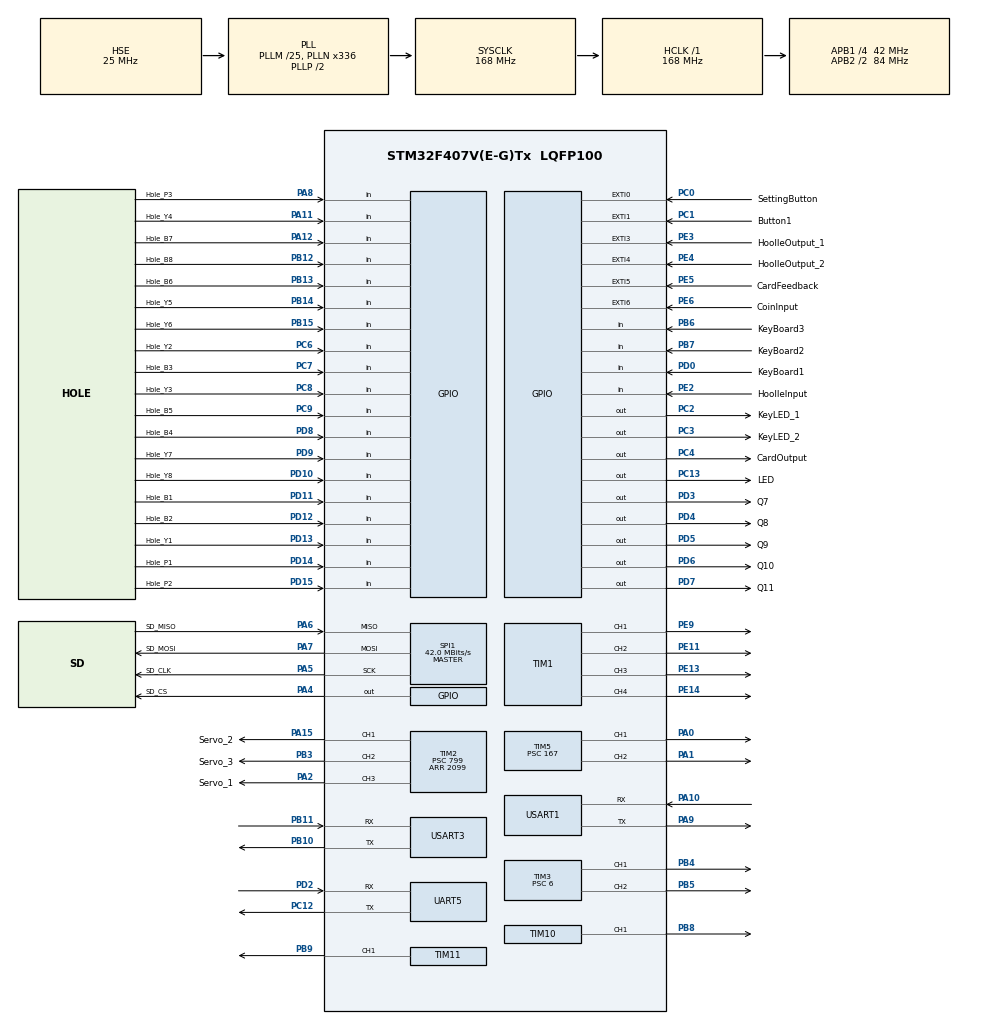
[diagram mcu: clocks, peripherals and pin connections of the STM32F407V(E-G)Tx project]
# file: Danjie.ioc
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Dma.Request0=TIM3_CH1/TRIG
Dma.Request1=TIM3_CH2
Dma.TIM3_CH1/TRIG.0.Direction=DMA_MEMORY_TO_PERIPH
Dma.TIM3_CH1/TRIG.0.FIFOMode=DMA_FIFOMODE_DISABLE
Dma.TIM3_CH1/TRIG.0.Instance=DMA1_Stream4
Dma.TIM3_CH1/TRIG.0.MemDataAlignment=DMA_MDATAALIGN_HALFWORD
Dma.TIM3_CH1/TRIG.0.MemInc=DMA_MINC_ENABLE
Dma.TIM3_CH1/TRIG.0.Mode=DMA_NORMAL
Dma.TIM3_CH1/TRIG.0.PeriphDataAlignment=DMA_PDATAALIGN_HALFWORD
Dma.TIM3_CH1/TRIG.0.PeriphInc=DMA_PINC_DISABLE
Dma.TIM3_CH1/TRIG.0.Priority=DMA_PRIORITY_LOW
Dma.TIM3_CH2.1.Direction=DMA_MEMORY_TO_PERIPH
Dma.TIM3_CH2.1.FIFOMode=DMA_FIFOMODE_DISABLE
Dma.TIM3_CH2.1.Instance=DMA1_Stream5
Dma.TIM3_CH2.1.MemDataAlignment=DMA_MDATAALIGN_HALFWORD
Dma.TIM3_CH2.1.MemInc=DMA_MINC_ENABLE
Dma.TIM3_CH2.1.Mode=DMA_NORMAL
Dma.TIM3_CH2.1.PeriphDataAlignment=DMA_PDATAALIGN_HALFWORD
Dma.TIM3_CH2.1.PeriphInc=DMA_PINC_DISABLE
Dma.TIM3_CH2.1.Priority=DMA_PRIORITY_LOW
IWDG.Prescaler=IWDG_PRESCALER_128
IWDG.Reload=3000
Mcu.Family=STM32F4
Mcu.Name=STM32F407V(E-G)Tx
Mcu.Package=LQFP100
NVIC.DMA1_Stream4_IRQn=true\:0\:0\:false\:false\:true\:false\:true\:true
NVIC.DMA1_Stream5_IRQn=true\:0\:0\:false\:false\:true\:false\:true\:true
NVIC.EXTI0_IRQn=true\:0\:0\:false\:false\:true\:true\:true\:true
NVIC.EXTI3_IRQn=true\:0\:0\:false\:false\:true\:true\:true\:true
NVIC.EXTI4_IRQn=true\:0\:0\:false\:false\:true\:true\:true\:true
NVIC.EXTI9_5_IRQn=true\:0\:0\:false\:false\:true\:true\:true\:true
NVIC.PriorityGroup=NVIC_PRIORITYGROUP_4
NVIC.USART1_IRQn=true\:0\:0\:false\:false\:true\:true\:true\:true
NVIC.USART3_IRQn=true\:0\:0\:false\:false\:true\:true\:true\:true
PA0-WKUP.Signal=S_TIM5_CH1
PA1.Signal=S_TIM5_CH2
PA10.GPIO_PuPd=GPIO_PULLUP
PA10.Mode=Asynchronous
PA10.Signal=USART1_RX
PA11.GPIO_Label=Hole_Y4
PA11.Signal=GPIO_Input
PA12.GPIO_Label=Hole_B7
PA12.Signal=GPIO_Input
PA13.Mode=Serial_Wire
PA13.Signal=SYS_JTMS-SWDIO
PA14.Mode=Serial_Wire
PA14.Signal=SYS_JTCK-SWCLK
PA15.GPIO_Label=Servo_2
PA15.Signal=S_TIM2_CH1_ETR
PA2.GPIO_Label=Servo_1
PA2.Signal=S_TIM2_CH3
PA4.GPIO_Label=SD_CS
PA4.Signal=GPIO_Output
PA5.GPIO_Label=SD_CLK
PA5.Mode=Full_Duplex_Master
PA5.Signal=SPI1_SCK
PA6.GPIO_Label=SD_MISO
PA6.Mode=Full_Duplex_Master
PA6.Signal=SPI1_MISO
PA7.GPIO_Label=SD_MOSI
PA7.Mode=Full_Duplex_Master
PA7.Signal=SPI1_MOSI
PA8.GPIO_Label=Hole_P3
PA8.Signal=GPIO_Input
PA9.Mode=Asynchronous
PA9.Signal=USART1_TX
PB10.Mode=Asynchronous
PB10.Signal=USART3_TX
PB11.Mode=Asynchronous
PB11.Signal=USART3_RX
PB12.GPIO_Label=Hole_B8
PB12.Signal=GPIO_Input
PB13.GPIO_Label=Hole_B6
PB13.Signal=GPIO_Input
PB14.GPIO_Label=Hole_Y5
PB14.Signal=GPIO_Input
PB15.GPIO_Label=Hole_Y6
PB15.Signal=GPIO_Input
PB3.GPIO_Label=Servo_3
PB3.Signal=S_TIM2_CH2
PB4.GPIO_Speed=GPIO_SPEED_FREQ_VERY_HIGH
PB4.Signal=S_TIM3_CH1
PB5.GPIO_Speed=GPIO_SPEED_FREQ_VERY_HIGH
PB5.Signal=S_TIM3_CH2
PB6.GPIO_Label=KeyBoard3
PB6.Signal=GPIO_Input
PB7.GPIO_Label=KeyBoard2
PB7.Signal=GPIO_Input
PB8.Signal=S_TIM10_CH1
PB9.Signal=S_TIM11_CH1
PC0.GPIO_Label=SettingButton
PC0.Signal=GPXTI0
PC1.GPIO_Label=Button1
PC1.Signal=GPXTI1
PC12.Mode=Asynchronous
PC12.Signal=UART5_TX
PC13-ANTI_TAMP.GPIO_Label=LED
PC13-ANTI_TAMP.PinState=GPIO_PIN_SET
PC13-ANTI_TAMP.Signal=GPIO_Output
PC2.GPIO_Label=KeyLED_1
PC2.Signal=GPIO_Output
PC3.GPIO_Label=KeyLED_2
PC3.Signal=GPIO_Output
PC4.GPIO_Label=CardOutput
PC4.Signal=GPIO_Output
PC6.GPIO_Label=Hole_Y2
PC6.Signal=GPIO_Input
PC7.GPIO_Label=Hole_B3
PC7.Signal=GPIO_Input
PC8.GPIO_Label=Hole_Y3
PC8.Signal=GPIO_Input
PC9.GPIO_Label=Hole_B5
PC9.Signal=GPIO_Input
PD0.GPIO_Label=KeyBoard1
PD0.Signal=GPIO_Input
PD10.GPIO_Label=Hole_Y8
PD10.Signal=GPIO_Input
PD11.GPIO_Label=Hole_B1
PD11.Signal=GPIO_Input
PD12.GPIO_Label=Hole_B2
PD12.Signal=GPIO_Input
PD13.GPIO_Label=Hole_Y1
PD13.Signal=GPIO_Input
PD14.GPIO_Label=Hole_P1
PD14.Signal=GPIO_Input
PD15.GPIO_Label=Hole_P2
PD15.Signal=GPIO_Input
PD2.Mode=Asynchronous
PD2.Signal=UART5_RX
PD3.GPIO_Label=Q7
PD3.Signal=GPIO_Output
PD4.GPIO_Label=Q8
PD4.Signal=GPIO_Output
PD5.GPIO_Label=Q9
PD5.Signal=GPIO_Output
PD6.GPIO_Label=Q10
PD6.Signal=GPIO_Output
PD7.GPIO_Label=Q11
PD7.Signal=GPIO_Output
PD8.GPIO_Label=Hole_B4
PD8.Signal=GPIO_Input
PD9.GPIO_Label=Hole_Y7
PD9.Signal=GPIO_Input
PE11.Signal=S_TIM1_CH2
PE13.Signal=S_TIM1_CH3
PE14.Signal=S_TIM1_CH4
PE2.GPIO_Label=HoolleInput
PE2.Signal=GPIO_Input
PE3.GPIO_Label=HoolleOutput_1
PE3.GPIO_ModeDefaultEXTI=GPIO_MODE_IT_RISING_FALLING
PE3.Signal=GPXTI3
PE4.GPIO_Label=HoolleOutput_2
PE4.GPIO_ModeDefaultEXTI=GPIO_MODE_IT_RISING_FALLING
PE4.Signal=GPXTI4
PE5.GPIO_Label=CardFeedback
PE5.Signal=GPXTI5
PE6.GPIO_Label=CoinInput
PE6.Signal=GPXTI6
PE9.Signal=S_TIM1_CH1
PH0-OSC_IN.Mode=HSE-External-Oscillator
PH0-OSC_IN.Signal=RCC_OSC_IN
PH1-OSC_OUT.Mode=HSE-External-Oscillator
PH1-OSC_OUT.Signal=RCC_OSC_OUT
ProjectManager.HeapSize=0x2000
ProjectManager.StackSize=0x2000
ProjectManager.TargetToolchain=MDK-ARM V5.32
RCC.48MHZClocksFreq_Value=84000000
RCC.AHBFreq_Value=168000000
RCC.APB1CLKDivider=RCC_HCLK_DIV4
RCC.APB1Freq_Value=42000000
RCC.APB1TimFreq_Value=84000000
RCC.APB2CLKDivider=RCC_HCLK_DIV2
RCC.APB2Freq_Value=84000000
RCC.APB2TimFreq_Value=168000000
RCC.CortexFreq_Value=168000000
RCC.HCLKFreq_Value=168000000
RCC.HSE_Timout=3000
RCC.HSE_VALUE=25000000
RCC.HSI_VALUE=16000000
RCC.LSE_VALUE=32768
RCC.PLLM=25
RCC.PLLN=336
RCC.PLLSourceVirtual=RCC_PLLSOURCE_HSE
RCC.SYSCLKFreq_VALUE=168000000
RCC.SYSCLKSource=RCC_SYSCLKSOURCE_PLLCLK
RCC.VCOOutputFreq_Value=336000000
SH.S_TIM10_CH1.0=TIM10_CH1,PWM Generation1 CH1
SH.S_TIM11_CH1.0=TIM11_CH1,PWM Generation1 CH1
SH.S_TIM1_CH1.0=TIM1_CH1,PWM Generation1 CH1
SH.S_TIM1_CH2.0=TIM1_CH2,PWM Generation2 CH2
SH.S_TIM1_CH3.0=TIM1_CH3,PWM Generation3 CH3
SH.S_TIM1_CH4.0=TIM1_CH4,PWM Generation4 CH4
SH.S_TIM2_CH1_ETR.0=TIM2_CH1,PWM Generation1 CH1
SH.S_TIM2_CH2.0=TIM2_CH2,PWM Generation2 CH2
SH.S_TIM2_CH3.0=TIM2_CH3,PWM Generation3 CH3
SH.S_TIM3_CH1.0=TIM3_CH1,PWM Generation1 CH1
SH.S_TIM3_CH2.0=TIM3_CH2,PWM Generation2 CH2
SH.S_TIM5_CH1.0=TIM5_CH1,PWM Generation1 CH1
SH.S_TIM5_CH2.0=TIM5_CH2,PWM Generation2 CH2
SPI1.BaudRatePrescaler=SPI_BAUDRATEPRESCALER_2
SPI1.CalculateBaudRate=42.0 MBits/s
SPI1.Direction=SPI_DIRECTION_2LINES
SPI1.Mode=SPI_MODE_MASTER
SPI1.VirtualType=VM_MASTER
TIM1.Channel-PWM\ Generation1\ CH1=TIM_CHANNEL_1
TIM1.Channel-PWM\ Generation2\ CH2=TIM_CHANNEL_2
TIM1.Channel-PWM\ Generation3\ CH3=TIM_CHANNEL_3
TIM1.Channel-PWM\ Generation4\ CH4=TIM_CHANNEL_4
TIM10.AutoReloadPreload=TIM_AUTORELOAD_PRELOAD_ENABLE
TIM10.Channel=TIM_CHANNEL_1
TIM10.Period=999
TIM10.Prescaler=167
TIM11.AutoReloadPreload=TIM_AUTORELOAD_PRELOAD_ENABLE
TIM11.Channel=TIM_CHANNEL_1
TIM11.Period=999
TIM11.Prescaler=167
TIM2.AutoReloadPreload=TIM_AUTORELOAD_PRELOAD_ENABLE
TIM2.Channel-PWM\ Generation1\ CH1=TIM_CHANNEL_1
TIM2.Channel-PWM\ Generation2\ CH2=TIM_CHANNEL_2
TIM2.Channel-PWM\ Generation3\ CH3=TIM_CHANNEL_3
TIM2.OCPolarity_1=TIM_OCPOLARITY_LOW
TIM2.OCPolarity_2=TIM_OCPOLARITY_LOW
TIM2.OCPolarity_3=TIM_OCPOLARITY_LOW
TIM2.Period=2099
TIM2.Prescaler=799
TIM2.Pulse-PWM\ Generation1\ CH1=157
TIM3.AutoReloadPreload=TIM_AUTORELOAD_PRELOAD_ENABLE
TIM3.Channel-PWM\ Generation1\ CH1=TIM_CHANNEL_1
TIM3.Channel-PWM\ Generation2\ CH2=TIM_CHANNEL_2
TIM3.OCPolarity_1=TIM_OCPOLARITY_HIGH
TIM3.OCPolarity_2=TIM_OCPOLARITY_HIGH
TIM3.Period=14
TIM3.Prescaler=6
TIM5.AutoReloadPreload=TIM_AUTORELOAD_PRELOAD_ENABLE
TIM5.Channel-PWM\ Generation1\ CH1=TIM_CHANNEL_1
TIM5.Channel-PWM\ Generation2\ CH2=TIM_CHANNEL_2
TIM5.Period=999
TIM5.Prescaler=167
TIM7.AutoReloadPreload=TIM_AUTORELOAD_PRELOAD_ENABLE
TIM7.Period=9999
TIM7.Prescaler=8399
UART5.VirtualMode=Asynchronous
USART1.VirtualMode=VM_ASYNC
USART3.VirtualMode=VM_ASYNC
VP_IWDG_VS_IWDG.Mode=IWDG_Activate
VP_TIM10_VS_ClockSourceINT.Mode=Enable_Timer
VP_TIM11_VS_ClockSourceINT.Mode=Enable_Timer
VP_TIM1_VS_ClockSourceINT.Mode=Internal
VP_TIM2_VS_ClockSourceINT.Mode=Internal
VP_TIM3_VS_ClockSourceINT.Mode=Internal
VP_TIM5_VS_ClockSourceINT.Mode=Internal
VP_TIM7_VS_ClockSourceINT.Mode=Enable_Timer
board=custom

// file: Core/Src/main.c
/* USER CODE BEGIN Header */
/**
  ******************************************************************************
  * @file           : main.c
  * @brief          : Main program body
  ******************************************************************************
  * @attention
  *
  * Copyright (c) 2026 STMicroelectronics.
  * All rights reserved.
  *
  * This software is licensed under terms that can be found in the LICENSE file
  * in the root directory of this software component.
  * If no LICENSE file comes with this software, it is provided AS-IS.
  *
  ******************************************************************************
  */
/* USER CODE END Header */
#include "main.h"
#include "dma.h"
#include "iwdg.h"
#include "spi.h"
#include "tim.h"
#include "usart.h"
#include "gpio.h"

/* USER CODE BEGIN Includes */
#include "MainTask.h"
/* USER CODE END Includes */

void SystemClock_Config(void);

int main(void)
{

  /* USER CODE BEGIN 1 */
  __enable_irq();
  /* USER CODE END 1 */

  /* MCU Configuration--------------------------------------------------------*/

  /* Reset of all peripherals, Initializes the Flash interface and the Systick. */
  HAL_Init();

  /* Configure the system clock */
  SystemClock_Config();

  /* Initialize all configured peripherals */
  MX_GPIO_Init();
  MX_DMA_Init();
  MX_SPI1_Init();
  MX_TIM1_Init();
  MX_TIM2_Init();
  MX_TIM3_Init();
  MX_UART5_Init();
  MX_USART1_UART_Init();
  MX_TIM7_Init();
  MX_IWDG_Init();
  MX_TIM5_Init();
  MX_TIM10_Init();
  MX_TIM11_Init();
  MX_USART3_UART_Init();
  /* USER CODE BEGIN 2 */
  Main_Init();
  /* USER CODE END 2 */

  /* Infinite loop */
  /* USER CODE BEGIN WHILE */
  while (1)
  {
    Main_Task();
    /* USER CODE END WHILE */

  }
}

void SystemClock_Config(void)
{
  RCC_OscInitTypeDef RCC_OscInitStruct = {0};
  RCC_ClkInitTypeDef RCC_ClkInitStruct = {0};

  /** Configure the main internal regulator output voltage
  */
  __HAL_RCC_PWR_CLK_ENABLE();
  __HAL_PWR_VOLTAGESCALING_CONFIG(PWR_REGULATOR_VOLTAGE_SCALE1);

  /** Initializes the RCC Oscillators according to the specified parameters
  * in the RCC_OscInitTypeDef structure.
  */
  RCC_OscInitStruct.OscillatorType = RCC_OSCILLATORTYPE_LSI|RCC_OSCILLATORTYPE_HSE;
  RCC_OscInitStruct.HSEState = RCC_HSE_ON;
  RCC_OscInitStruct.LSIState = RCC_LSI_ON;
  RCC_OscInitStruct.PLL.PLLState = RCC_PLL_ON;
  RCC_OscInitStruct.PLL.PLLSource = RCC_PLLSOURCE_HSE;
  RCC_OscInitStruct.PLL.PLLM = 25;
  RCC_OscInitStruct.PLL.PLLN = 336;
  RCC_OscInitStruct.PLL.PLLP = RCC_PLLP_DIV2;
  RCC_OscInitStruct.PLL.PLLQ = 4;
  if (HAL_RCC_OscConfig(&RCC_OscInitStruct) != HAL_OK)
  {
    Error_Handler();
  }

  /** Initializes the CPU, AHB and APB buses clocks
  */
  RCC_ClkInitStruct.ClockType = RCC_CLOCKTYPE_HCLK|RCC_CLOCKTYPE_SYSCLK
                              |RCC_CLOCKTYPE_PCLK1|RCC_CLOCKTYPE_PCLK2;
  RCC_ClkInitStruct.SYSCLKSource = RCC_SYSCLKSOURCE_PLLCLK;
  RCC_ClkInitStruct.AHBCLKDivider = RCC_SYSCLK_DIV1;
  RCC_ClkInitStruct.APB1CLKDivider = RCC_HCLK_DIV4;
  RCC_ClkInitStruct.APB2CLKDivider = RCC_HCLK_DIV2;

  if (HAL_RCC_ClockConfig(&RCC_ClkInitStruct, FLASH_LATENCY_5) != HAL_OK)
  {
    Error_Handler();
  }
}

void Error_Handler(void)
{
  __disable_irq();
  while (1)
  {
  }
}
